# FGEN register map
Vendor: litex
Registers are 32-bit, read-write, reset 0x0 unless marked. A register's access mark holds for its fields unless they carry their own. Offsets are from the block's base; lines under a group give offsets from that group; [hi:lo] are bit positions; {n}, {i} and the like mark numbered series; 'fields as' and 'values as' point back to an identical list; <NAME> marks a mode.

## Memory map
0xE0000000 CTRL size 0xC
0xE0001800 UART size 0x30
0xE0002000 TIMER0 size 0x20
0xE0002800 SPIFLASH size 0xC
0xE0003000 LEDS size 0x4
0xE0003800 GPIOB size 0xC
0xE0004000 FGEN_LUT size 0x4
0xE0004800 FGEN size 0x10

## Interrupts
0 uart (UART)
1 timer0 (TIMER0)

## CTRL
Base 0xE0000000
0x00 RESET — Write a ``1`` to this register to reset the SoC.
  [0] reset
0x04 SCRATCH reset 0x12345678 — Use this register as a scratch space to verify that software read/write accesses to the Wishbone/CSR bus are working correctly. The initial reset value of 0x1234578 can be used to verify endianness.
0x08 BUS_ERRORS ro — Total number of Wishbone bus errors (timeouts) since last reset.

## UART
Base 0xE0001800
0x00 RXTX
  [7:0] rxtx
0x04 TXFULL ro
  [0] txfull
0x08 RXEMPTY ro
  [0] rxempty
0x0C EV_STATUS
  [1:0] status
0x10 EV_PENDING
  [1:0] pending
0x14 EV_ENABLE
  [1:0] enable
0x18 XOVER_RXTX
  [7:0] xover_rxtx
0x1C XOVER_TXFULL ro
  [0] xover_txfull
0x20 XOVER_RXEMPTY ro
  [0] xover_rxempty
0x24 XOVER_EV_STATUS
  [1:0] xover_ev_status
0x28 XOVER_EV_PENDING
  [1:0] xover_ev_pending
0x2C XOVER_EV_ENABLE
  [1:0] xover_ev_enable

## TIMER0
Base 0xE0002000
0x00 LOAD — Load value when Timer is (re-)enabled. In One-Shot mode, the value written to this register specifies the Timer's duration in clock cycles.
0x04 RELOAD — Reload value when Timer reaches ``0``. In Periodic mode, the value written to this register specify the Timer's period in clock cycles.
0x08 EN — Enable flag of the Timer. Set this flag to ``1`` to enable/start the Timer. Set to ``0`` to disable the Timer.
  [0] en
0x0C UPDATE_VALUE — Update trigger for the current countdown value. A write to this register latches the current countdown value to ``value`` register.
  [0] update_value
0x10 VALUE ro — Latched countdown value. This value is updated by writing to ``update_value``.
0x14 EV_STATUS
  [0] status
0x18 EV_PENDING
  [0] pending
0x1C EV_ENABLE
  [0] enable

## SPIFLASH
Base 0xE0002800
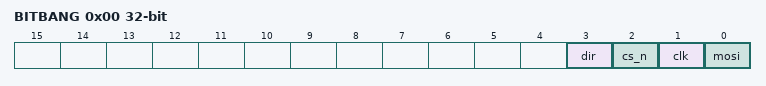
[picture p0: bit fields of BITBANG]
0x00 BITBANG — Bitbang controls for SPI output. Only standard 1x SPI is supported, and as a result all four wires are ganged together. This means that it is only possible to perform half-duplex operations, using this SPI core.
  [3] dir — Sets the direction for *ALL* SPI data pins except CLK and CSn.
  [2] cs_n — Output value for SPI CSn pin.
  [1] clk — Output value for SPI CLK pin.
  [0] mosi — Output value for MOSI pin, valid whenever ``dir`` is ``0``.
0x04 MISO ro — Incoming value of MISO signal.
  [0] miso
0x08 BITBANG_EN — Write a ``1`` here to disable memory-mapped mode and enable bitbang mode.
  [0] bitbang_en

## LEDS
Base 0xE0003000
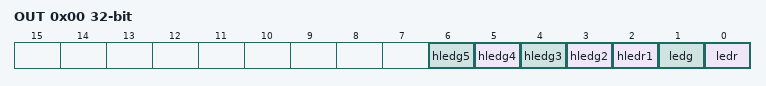
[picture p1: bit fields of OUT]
0x00 OUT
  [n+1] hledg{n} (n=2..5) — Green LED #{n} on the iCEBreaker head.
  [2] hledr1 — The center Red LED #1 on the iCEBreaker head.
  [1] ledg — The Green LED on the main iCEBreaker board.
  [0] ledr — The Red LED on the main iCEBreaker board.

## GPIOB
Base 0xE0003800
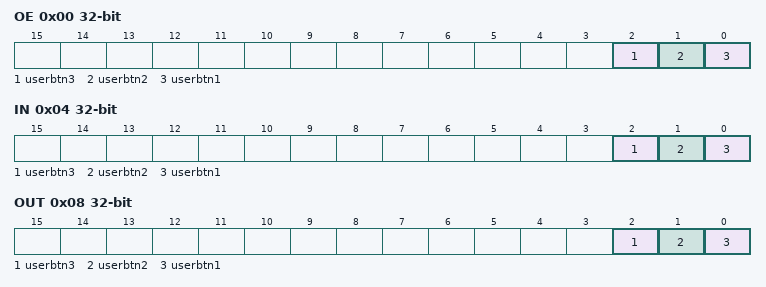
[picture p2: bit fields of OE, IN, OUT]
0x00 OE — GPIO Tristate(s) Control.
  [2] userbtn3 — The Button 3
  [1] userbtn2 — The Button 2
  [0] userbtn1 — The Button 1
0x04 IN ro — GPIO Input(s) Status.
  fields as OE
0x08 OUT — GPIO Output(s) Control.
  fields as OE

## FGEN_LUT
Base 0xE0004000
{0x0+4i} FGEN_LUT[{i}] (i=0..511) — 32 x 2048-bit memory
  [31:0] fgen_lut

## FGEN
Base 0xE0004800
0x00 EN
  [0] enable — Enable function generator
0x04 FCW
  [16:0] fcw — Function generator frequency control word
0x08 PRESCALER
  [31:0] prescaler — Function generator clock prescaler
0x0C LUT_PAGE
  [1:0] lut_page
